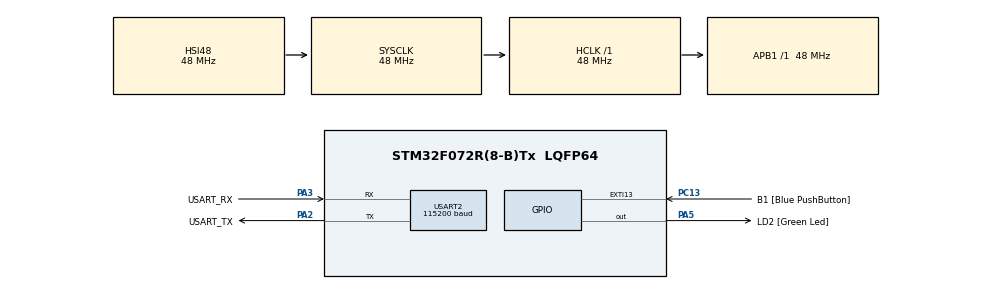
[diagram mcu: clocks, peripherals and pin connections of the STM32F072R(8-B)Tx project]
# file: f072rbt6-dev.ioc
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Dma.Request0=USART2_RX
Dma.USART2_RX.0.Direction=DMA_PERIPH_TO_MEMORY
Dma.USART2_RX.0.Instance=DMA1_Channel5
Dma.USART2_RX.0.MemDataAlignment=DMA_MDATAALIGN_BYTE
Dma.USART2_RX.0.MemInc=DMA_MINC_ENABLE
Dma.USART2_RX.0.Mode=DMA_NORMAL
Dma.USART2_RX.0.PeriphDataAlignment=DMA_PDATAALIGN_BYTE
Dma.USART2_RX.0.PeriphInc=DMA_PINC_DISABLE
Dma.USART2_RX.0.Priority=DMA_PRIORITY_LOW
FREERTOS.Tasks01=defaultTask,24,128,StartDefaultTask,Default,NULL,Dynamic,NULL,NULL
Mcu.Family=STM32F0
Mcu.Name=STM32F072R(8-B)Tx
Mcu.Package=LQFP64
NVIC.DMA1_Channel4_5_6_7_IRQn=true\:3\:0\:false\:false\:true\:true\:false\:true
NVIC.TIM7_IRQn=true\:3\:0\:false\:false\:true\:false\:false\:true
NVIC.TimeBase=TIM7_IRQn
NVIC.TimeBaseIP=TIM7
NVIC.USART2_IRQn=true\:3\:0\:false\:true\:true\:1\:true\:true\:true
PA13.GPIO_Label=TMS
PA13.Mode=Serial_Wire
PA13.Signal=SYS_SWDIO
PA14.GPIO_Label=TCK
PA14.Mode=Serial_Wire
PA14.Signal=SYS_SWCLK
PA2.GPIO_Label=USART_TX
PA2.GPIO_Mode=GPIO_MODE_AF_PP
PA2.GPIO_PuPd=GPIO_NOPULL
PA2.GPIO_Speed=GPIO_SPEED_FREQ_LOW
PA2.Mode=Asynchronous
PA2.Signal=USART2_TX
PA3.GPIO_Label=USART_RX
PA3.GPIO_Mode=GPIO_MODE_AF_PP
PA3.GPIO_PuPd=GPIO_NOPULL
PA3.GPIO_Speed=GPIO_SPEED_FREQ_LOW
PA3.Mode=Asynchronous
PA3.Signal=USART2_RX
PA5.GPIO_Label=LD2 [Green Led]
PA5.GPIO_Mode=GPIO_MODE_OUTPUT_PP
PA5.GPIO_PuPd=GPIO_NOPULL
PA5.GPIO_Speed=GPIO_SPEED_FREQ_LOW
PA5.Signal=GPIO_Output
PC13.GPIO_Label=B1 [Blue PushButton]
PC13.GPIO_ModeDefaultEXTI=GPIO_MODE_IT_FALLING
PC13.Signal=GPXTI13
PC14-OSC32_IN.Mode=LSE-External-Oscillator
PC14-OSC32_IN.Signal=RCC_OSC32_IN
PC15-OSC32_OUT.Mode=LSE-External-Oscillator
PC15-OSC32_OUT.Signal=RCC_OSC32_OUT
PF0-OSC_IN.Mode=HSE-External-Clock-Source
PF0-OSC_IN.Signal=RCC_OSC_IN
PF1-OSC_OUT.Signal=RCC_OSC_OUT
ProjectManager.HeapSize=0x200
ProjectManager.StackSize=0x400
ProjectManager.TargetToolchain=STM32CubeIDE
RCC.AHBFreq_Value=48000000
RCC.APB1Freq_Value=48000000
RCC.APB1TimFreq_Value=48000000
RCC.FLatency-AdvancedSettings=FLASH_LATENCY_1
RCC.HCLKFreq_Value=48000000
RCC.PLLDivider=RCC_PREDIV_DIV2
RCC.PLLMUL=RCC_PLL_MUL12
RCC.PREFETCH_ENABLE-AdvancedSettings=1
RCC.SYSCLKFreq_VALUE=48000000
RCC.SYSCLKSource=RCC_SYSCLKSOURCE_HSI48
USART2.BaudRate=115200
USART2.VirtualMode=VM_ASYNC
USART2.VirtualMode-Asynchronous=VM_ASYNC
VP_FREERTOS_VS_CMSIS_V2.Mode=CMSIS_V2
VP_SYS_VS_tim7.Mode=TIM7
board=NUCLEO-F072RB

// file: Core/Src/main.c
/* USER CODE BEGIN Header */
/**
  ******************************************************************************
  * @file           : main.c
  * @brief          : Main program body
  ******************************************************************************
  * @attention
  *
  * Copyright (c) 2023 STMicroelectronics.
  * All rights reserved.
  *
  * This software is licensed under terms that can be found in the LICENSE file
  * in the root directory of this software component.
  * If no LICENSE file comes with this software, it is provided AS-IS.
  *
  ******************************************************************************
  */
/* USER CODE END Header */
#include "main.h"
#include "cmsis_os.h"

UART_HandleTypeDef huart2;
DMA_HandleTypeDef hdma_usart2_rx;

/* Definitions for defaultTask */
osThreadId_t defaultTaskHandle;
const osThreadAttr_t defaultTask_attributes = {
  .name = "defaultTask",
  .stack_size = 128 * 4,
  .priority = (osPriority_t) osPriorityNormal,
};

void SystemClock_Config(void);
static void MX_GPIO_Init(void);
static void MX_USART2_UART_Init(void);
static void MX_DMA_Init(void);
void StartDefaultTask(void *argument);

static void MX_NVIC_Init(void);
/* USER CODE BEGIN PFP */
void CPP_UserSetup(void);
/* USER CODE END PFP */

int main(void)
{

  /* MCU Configuration--------------------------------------------------------*/

  /* Reset of all peripherals, Initializes the Flash interface and the Systick. */
  HAL_Init();

  /* Configure the system clock */
  SystemClock_Config();

  /* Initialize all configured peripherals */
  MX_GPIO_Init();
  MX_DMA_Init();
  MX_USART2_UART_Init();

  /* Initialize interrupts */
  MX_NVIC_Init();
  /* USER CODE BEGIN 2 */
  CPP_UserSetup();
  /* USER CODE END 2 */

  /* Init scheduler */
  osKernelInitialize();

  /* Create the thread(s) */
  /* creation of defaultTask */
  defaultTaskHandle = osThreadNew(StartDefaultTask, NULL, &defaultTask_attributes);

  /* Start scheduler */
  osKernelStart();

  /* We should never get here as control is now taken by the scheduler */
  /* Infinite loop */
  while (1)
  {

  }
}

void SystemClock_Config(void)
{
  RCC_OscInitTypeDef RCC_OscInitStruct = {0};
  RCC_ClkInitTypeDef RCC_ClkInitStruct = {0};
  RCC_PeriphCLKInitTypeDef PeriphClkInit = {0};

  /** Initializes the RCC Oscillators according to the specified parameters
  * in the RCC_OscInitTypeDef structure.
  */
  RCC_OscInitStruct.OscillatorType = RCC_OSCILLATORTYPE_HSI48;
  RCC_OscInitStruct.HSI48State = RCC_HSI48_ON;
  RCC_OscInitStruct.PLL.PLLState = RCC_PLL_NONE;
  if (HAL_RCC_OscConfig(&RCC_OscInitStruct) != HAL_OK)
  {
    Error_Handler();
  }
  /** Initializes the CPU, AHB and APB buses clocks
  */
  RCC_ClkInitStruct.ClockType = RCC_CLOCKTYPE_HCLK|RCC_CLOCKTYPE_SYSCLK
                              |RCC_CLOCKTYPE_PCLK1;
  RCC_ClkInitStruct.SYSCLKSource = RCC_SYSCLKSOURCE_HSI48;
  RCC_ClkInitStruct.AHBCLKDivider = RCC_SYSCLK_DIV1;
  RCC_ClkInitStruct.APB1CLKDivider = RCC_HCLK_DIV1;

  if (HAL_RCC_ClockConfig(&RCC_ClkInitStruct, FLASH_LATENCY_1) != HAL_OK)
  {
    Error_Handler();
  }
  PeriphClkInit.PeriphClockSelection = RCC_PERIPHCLK_USART2;
  PeriphClkInit.Usart2ClockSelection = RCC_USART2CLKSOURCE_PCLK1;
  if (HAL_RCCEx_PeriphCLKConfig(&PeriphClkInit) != HAL_OK)
  {
    Error_Handler();
  }
}

/**
  * @brief NVIC Configuration.
  * @retval None
  */
static void MX_NVIC_Init(void)
{
  /* USART2_IRQn interrupt configuration */
  HAL_NVIC_SetPriority(USART2_IRQn, 3, 0);
  HAL_NVIC_EnableIRQ(USART2_IRQn);
}

static void MX_USART2_UART_Init(void)
{

  huart2.Instance = USART2;
  huart2.Init.BaudRate = 115200;
  huart2.Init.WordLength = UART_WORDLENGTH_8B;
  huart2.Init.StopBits = UART_STOPBITS_1;
  huart2.Init.Parity = UART_PARITY_NONE;
  huart2.Init.Mode = UART_MODE_TX_RX;
  huart2.Init.HwFlowCtl = UART_HWCONTROL_NONE;
  huart2.Init.OverSampling = UART_OVERSAMPLING_16;
  huart2.Init.OneBitSampling = UART_ONE_BIT_SAMPLE_DISABLE;
  huart2.AdvancedInit.AdvFeatureInit = UART_ADVFEATURE_NO_INIT;
  if (HAL_UART_Init(&huart2) != HAL_OK)
  {
    Error_Handler();
  }

}

static void MX_DMA_Init(void)
{

  /* DMA controller clock enable */
  __HAL_RCC_DMA1_CLK_ENABLE();

  /* DMA interrupt init */
  /* DMA1_Channel4_5_6_7_IRQn interrupt configuration */
  HAL_NVIC_SetPriority(DMA1_Channel4_5_6_7_IRQn, 3, 0);
  HAL_NVIC_EnableIRQ(DMA1_Channel4_5_6_7_IRQn);

}

static void MX_GPIO_Init(void)
{
  GPIO_InitTypeDef GPIO_InitStruct = {0};

  /* GPIO Ports Clock Enable */
  __HAL_RCC_GPIOC_CLK_ENABLE();
  __HAL_RCC_GPIOF_CLK_ENABLE();
  __HAL_RCC_GPIOA_CLK_ENABLE();

  /*Configure GPIO pin Output Level */
  HAL_GPIO_WritePin(LD2_GPIO_Port, LD2_Pin, GPIO_PIN_RESET);

  /*Configure GPIO pin : B1_Pin */
  GPIO_InitStruct.Pin = B1_Pin;
  GPIO_InitStruct.Mode = GPIO_MODE_IT_FALLING;
  GPIO_InitStruct.Pull = GPIO_NOPULL;
  HAL_GPIO_Init(B1_GPIO_Port, &GPIO_InitStruct);

  /*Configure GPIO pin : LD2_Pin */
  GPIO_InitStruct.Pin = LD2_Pin;
  GPIO_InitStruct.Mode = GPIO_MODE_OUTPUT_PP;
  GPIO_InitStruct.Pull = GPIO_NOPULL;
  GPIO_InitStruct.Speed = GPIO_SPEED_FREQ_LOW;
  HAL_GPIO_Init(LD2_GPIO_Port, &GPIO_InitStruct);

}

void StartDefaultTask(void *argument)
{
  /* USER CODE BEGIN 5 */
  /* Infinite loop */
  for(;;)
  {
    osDelay(1000);
  }
  /* USER CODE END 5 */
}

void HAL_TIM_PeriodElapsedCallback(TIM_HandleTypeDef *htim)
{
  if (htim->Instance == TIM7) {
    HAL_IncTick();
  }
}

void Error_Handler(void)
{
  __disable_irq();
  while (1)
  {
  }
}
